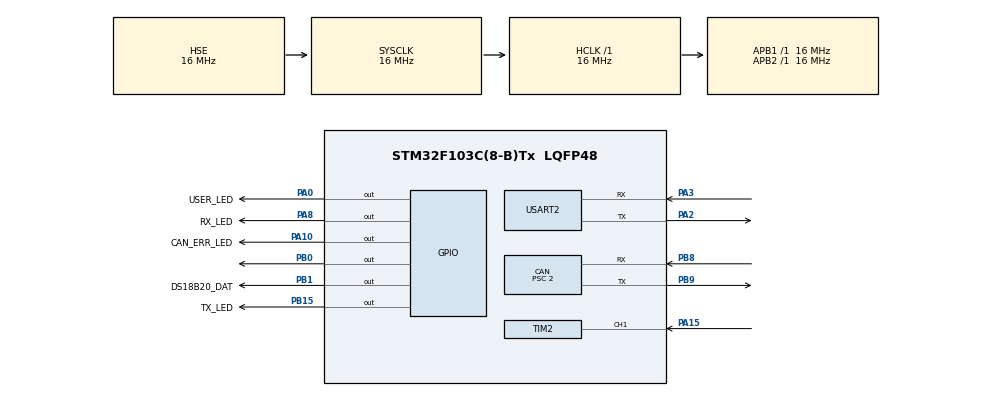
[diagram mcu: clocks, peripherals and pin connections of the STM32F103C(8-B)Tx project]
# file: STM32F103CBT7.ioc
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CAN.BS1=CAN_BS1_13TQ
CAN.BS2=CAN_BS2_2TQ
CAN.CalculateBaudRate=500000
CAN.CalculateTimeBit=2000
CAN.CalculateTimeQuantum=125.0
CAN.Prescaler=2
Mcu.Family=STM32F1
Mcu.Name=STM32F103C(8-B)Tx
Mcu.Package=LQFP48
NVIC.PriorityGroup=NVIC_PRIORITYGROUP_4
NVIC.USB_HP_CAN1_TX_IRQn=true\:0\:0\:false\:false\:true\:true\:true\:true
PA0-WKUP.GPIO_Label=USER_LED
PA0-WKUP.Signal=GPIO_Output
PA10.GPIO_Label=CAN_ERR_LED
PA10.Signal=GPIO_Output
PA13.Signal=SYS_JTMS-SWDIO
PA14.Signal=SYS_JTCK-SWCLK
PA15.Signal=S_TIM2_CH1_ETR
PA2.Mode=Asynchronous
PA2.Signal=USART2_TX
PA3.Mode=Asynchronous
PA3.Signal=USART2_RX
PA8.GPIO_Label=RX_LED
PA8.Signal=GPIO_Output
PB0.GPIO_ModeDefaultOutputPP=GPIO_MODE_OUTPUT_OD
PB0.GPIO_PuPd=GPIO_PULLUP
PB0.GPIO_Speed=GPIO_SPEED_FREQ_LOW
PB0.PinState=GPIO_PIN_RESET
PB0.Signal=GPIO_Output
PB1.GPIO_Label=DS18B20_DAT
PB1.GPIO_ModeDefaultOutputPP=GPIO_MODE_OUTPUT_PP
PB1.GPIO_PuPd=GPIO_NOPULL
PB1.Signal=GPIO_Output
PB15.GPIO_Label=TX_LED
PB15.Signal=GPIO_Output
PB3.Signal=SYS_JTDO-TRACESWO
PB8.Mode=CAN_Activate
PB8.Signal=CAN_RX
PB9.Mode=CAN_Activate
PB9.Signal=CAN_TX
PD0-OSC_IN.Mode=HSE-External-Oscillator
PD0-OSC_IN.Signal=RCC_OSC_IN
PD1-OSC_OUT.Mode=HSE-External-Oscillator
PD1-OSC_OUT.Signal=RCC_OSC_OUT
ProjectManager.HeapSize=0x200
ProjectManager.StackSize=0x400
ProjectManager.TargetToolchain=STM32CubeIDE
RCC.AHBFreq_Value=16000000
RCC.APB1Freq_Value=16000000
RCC.APB1TimFreq_Value=16000000
RCC.APB2Freq_Value=16000000
RCC.APB2TimFreq_Value=16000000
RCC.HCLKFreq_Value=16000000
RCC.HSE_VALUE=16000000
RCC.PLLMUL=RCC_PLL_MUL3
RCC.PLLSourceVirtual=RCC_PLLSOURCE_HSE
RCC.SYSCLKFreq_VALUE=16000000
RCC.SYSCLKSource=RCC_SYSCLKSOURCE_HSE
RCC.USBFreq_Value=48000000
SH.S_TIM2_CH1_ETR.0=TIM2_CH1,Input_Capture1_from_TI1
TIM2.Channel-Input_Capture1_from_TI1=TIM_CHANNEL_1
TIM2.Prescaler=15
USART2.VirtualMode=VM_ASYNC
VP_SYS_VS_ND.Mode=No_Debug
VP_TIM2_VS_ClockSourceINT.Mode=Internal
board=custom

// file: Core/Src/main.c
/* USER CODE BEGIN Header */
/**
 ******************************************************************************
 * @file           : main.c
 * @brief          : Main program body
 ******************************************************************************
 * @attention
 *
 * Copyright (c) 2026 STMicroelectronics.
 * All rights reserved.
 *
 * This software is licensed under terms that can be found in the LICENSE file
 * in the root directory of this software component.
 * If no LICENSE file comes with this software, it is provided AS-IS.
 *
 ******************************************************************************
 */
/* USER CODE END Header */
#include "main.h"

/* USER CODE BEGIN Includes */
#include "ds18b20.h"
#include "can.h"
/* USER CODE END Includes */

CAN_HandleTypeDef hcan;

TIM_HandleTypeDef htim2;

UART_HandleTypeDef huart2;

void SystemClock_Config(void);
static void MX_GPIO_Init(void);
static void MX_TIM2_Init(void);
static void MX_USART2_UART_Init(void);
static void MX_CAN_Init(void);

int main(void)
{

  /* MCU Configuration--------------------------------------------------------*/

  /* Reset of all peripherals, Initializes the Flash interface and the Systick. */
  HAL_Init();

  /* Configure the system clock */
  SystemClock_Config();

  /* Initialize all configured peripherals */
  MX_GPIO_Init();
  MX_TIM2_Init();
  MX_USART2_UART_Init();
  MX_CAN_Init();
  /* USER CODE BEGIN 2 */
	HAL_Delay(1000);

	HAL_GPIO_WritePin(USER_LED_GPIO_Port, USER_LED_Pin, GPIO_PIN_SET);

	ds18b20_init();

	can_init(&hcan);
  /* USER CODE END 2 */

  /* Infinite loop */
  /* USER CODE BEGIN WHILE */
	while (1) {
		ds18b20_update();

		can_update();

		HAL_Delay(100);
    /* USER CODE END WHILE */

	}
}

void SystemClock_Config(void)
{
  RCC_OscInitTypeDef RCC_OscInitStruct = {0};
  RCC_ClkInitTypeDef RCC_ClkInitStruct = {0};

  /** Initializes the RCC Oscillators according to the specified parameters
  * in the RCC_OscInitTypeDef structure.
  */
  RCC_OscInitStruct.OscillatorType = RCC_OSCILLATORTYPE_HSE;
  RCC_OscInitStruct.HSEState = RCC_HSE_ON;
  RCC_OscInitStruct.PLL.PLLState = RCC_PLL_NONE;
  if (HAL_RCC_OscConfig(&RCC_OscInitStruct) != HAL_OK)
  {
    Error_Handler();
  }

  /** Initializes the CPU, AHB and APB buses clocks
  */
  RCC_ClkInitStruct.ClockType = RCC_CLOCKTYPE_HCLK|RCC_CLOCKTYPE_SYSCLK
                              |RCC_CLOCKTYPE_PCLK1|RCC_CLOCKTYPE_PCLK2;
  RCC_ClkInitStruct.SYSCLKSource = RCC_SYSCLKSOURCE_HSE;
  RCC_ClkInitStruct.AHBCLKDivider = RCC_SYSCLK_DIV1;
  RCC_ClkInitStruct.APB1CLKDivider = RCC_HCLK_DIV1;
  RCC_ClkInitStruct.APB2CLKDivider = RCC_HCLK_DIV1;

  if (HAL_RCC_ClockConfig(&RCC_ClkInitStruct, FLASH_LATENCY_0) != HAL_OK)
  {
    Error_Handler();
  }
}

static void MX_CAN_Init(void)
{

  hcan.Instance = CAN1;
  hcan.Init.Prescaler = 2;
  hcan.Init.Mode = CAN_MODE_NORMAL;
  hcan.Init.SyncJumpWidth = CAN_SJW_1TQ;
  hcan.Init.TimeSeg1 = CAN_BS1_13TQ;
  hcan.Init.TimeSeg2 = CAN_BS2_2TQ;
  hcan.Init.TimeTriggeredMode = DISABLE;
  hcan.Init.AutoBusOff = DISABLE;
  hcan.Init.AutoWakeUp = DISABLE;
  hcan.Init.AutoRetransmission = DISABLE;
  hcan.Init.ReceiveFifoLocked = DISABLE;
  hcan.Init.TransmitFifoPriority = DISABLE;
  if (HAL_CAN_Init(&hcan) != HAL_OK)
  {
    Error_Handler();
  }

}

static void MX_TIM2_Init(void)
{

  TIM_ClockConfigTypeDef sClockSourceConfig = {0};
  TIM_MasterConfigTypeDef sMasterConfig = {0};
  TIM_IC_InitTypeDef sConfigIC = {0};

  htim2.Instance = TIM2;
  htim2.Init.Prescaler = 15;
  htim2.Init.CounterMode = TIM_COUNTERMODE_UP;
  htim2.Init.Period = 65535;
  htim2.Init.ClockDivision = TIM_CLOCKDIVISION_DIV1;
  htim2.Init.AutoReloadPreload = TIM_AUTORELOAD_PRELOAD_DISABLE;
  if (HAL_TIM_Base_Init(&htim2) != HAL_OK)
  {
    Error_Handler();
  }
  sClockSourceConfig.ClockSource = TIM_CLOCKSOURCE_INTERNAL;
  if (HAL_TIM_ConfigClockSource(&htim2, &sClockSourceConfig) != HAL_OK)
  {
    Error_Handler();
  }
  if (HAL_TIM_IC_Init(&htim2) != HAL_OK)
  {
    Error_Handler();
  }
  sMasterConfig.MasterOutputTrigger = TIM_TRGO_RESET;
  sMasterConfig.MasterSlaveMode = TIM_MASTERSLAVEMODE_DISABLE;
  if (HAL_TIMEx_MasterConfigSynchronization(&htim2, &sMasterConfig) != HAL_OK)
  {
    Error_Handler();
  }
  sConfigIC.ICPolarity = TIM_INPUTCHANNELPOLARITY_RISING;
  sConfigIC.ICSelection = TIM_ICSELECTION_DIRECTTI;
  sConfigIC.ICPrescaler = TIM_ICPSC_DIV1;
  sConfigIC.ICFilter = 0;
  if (HAL_TIM_IC_ConfigChannel(&htim2, &sConfigIC, TIM_CHANNEL_1) != HAL_OK)
  {
    Error_Handler();
  }

}

static void MX_USART2_UART_Init(void)
{

  huart2.Instance = USART2;
  huart2.Init.BaudRate = 115200;
  huart2.Init.WordLength = UART_WORDLENGTH_8B;
  huart2.Init.StopBits = UART_STOPBITS_1;
  huart2.Init.Parity = UART_PARITY_NONE;
  huart2.Init.Mode = UART_MODE_TX_RX;
  huart2.Init.HwFlowCtl = UART_HWCONTROL_NONE;
  huart2.Init.OverSampling = UART_OVERSAMPLING_16;
  if (HAL_UART_Init(&huart2) != HAL_OK)
  {
    Error_Handler();
  }

}

static void MX_GPIO_Init(void)
{
  GPIO_InitTypeDef GPIO_InitStruct = {0};

  /* GPIO Ports Clock Enable */
  __HAL_RCC_GPIOD_CLK_ENABLE();
  __HAL_RCC_GPIOA_CLK_ENABLE();
  __HAL_RCC_GPIOB_CLK_ENABLE();

  /*Configure GPIO pin Output Level */
  HAL_GPIO_WritePin(GPIOA, USER_LED_Pin|RX_LED_Pin|CAN_ERR_LED_Pin, GPIO_PIN_RESET);

  /*Configure GPIO pin Output Level */
  HAL_GPIO_WritePin(GPIOB, GPIO_PIN_0|DS18B20_DAT_Pin|TX_LED_Pin, GPIO_PIN_RESET);

  /*Configure GPIO pins : USER_LED_Pin RX_LED_Pin CAN_ERR_LED_Pin */
  GPIO_InitStruct.Pin = USER_LED_Pin|RX_LED_Pin|CAN_ERR_LED_Pin;
  GPIO_InitStruct.Mode = GPIO_MODE_OUTPUT_PP;
  GPIO_InitStruct.Pull = GPIO_NOPULL;
  GPIO_InitStruct.Speed = GPIO_SPEED_FREQ_LOW;
  HAL_GPIO_Init(GPIOA, &GPIO_InitStruct);

  /*Configure GPIO pin : PB0 */
  GPIO_InitStruct.Pin = GPIO_PIN_0;
  GPIO_InitStruct.Mode = GPIO_MODE_OUTPUT_OD;
  GPIO_InitStruct.Pull = GPIO_PULLUP;
  GPIO_InitStruct.Speed = GPIO_SPEED_FREQ_LOW;
  HAL_GPIO_Init(GPIOB, &GPIO_InitStruct);

  /*Configure GPIO pins : DS18B20_DAT_Pin TX_LED_Pin */
  GPIO_InitStruct.Pin = DS18B20_DAT_Pin|TX_LED_Pin;
  GPIO_InitStruct.Mode = GPIO_MODE_OUTPUT_PP;
  GPIO_InitStruct.Pull = GPIO_NOPULL;
  GPIO_InitStruct.Speed = GPIO_SPEED_FREQ_LOW;
  HAL_GPIO_Init(GPIOB, &GPIO_InitStruct);

}

/* USER CODE BEGIN 4 */
//void HAL_CAN_RxFifo0MsgPendingCallback(CAN_HandleTypeDef *hcan) {
//	if (HAL_CAN_GetRxMessage(hcan, CAN_RX_FIFO0, &rxHeader, rxData) != HAL_OK) {
//		return;
//	}
//
//	g_rx_id = (rxHeader.IDE == CAN_ID_STD) ? rxHeader.StdId : rxHeader.ExtId;
//	g_rx_len = rxHeader.DLC;
//	for (uint32_t i = 0; i < 8; i++) {
//		g_rx_buf[i] = rxData[i];
//	}
//	g_rx_flag = 1;
//}
//
void HAL_CAN_TxMailbox0CompleteCallback(CAN_HandleTypeDef *hcan) {
	can_tx_callback();
}

void HAL_CAN_ErrorCallback(CAN_HandleTypeDef *hcan) {
	can_error_callback();
}
/* USER CODE END 4 */

void Error_Handler(void)
{
	__disable_irq();
	while (1) {
	}
}
